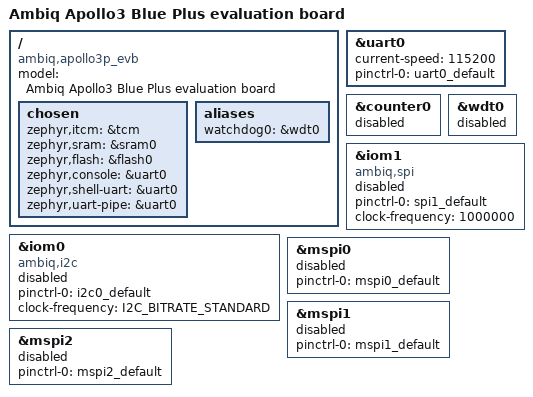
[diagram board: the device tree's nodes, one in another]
/dts-v1/;
#include <ambiq/ambiq_apollo3p_blue.dtsi>

#include "apollo3p_evb-pinctrl.dtsi"

/ {
	model = "Ambiq Apollo3 Blue Plus evaluation board";
	compatible = "ambiq,apollo3p_evb";

	chosen {
		zephyr,itcm = &tcm;
		zephyr,sram = &sram0;
		zephyr,flash = &flash0;
		zephyr,console = &uart0;
		zephyr,shell-uart = &uart0;
		zephyr,uart-pipe = &uart0;
	};

	aliases {
		watchdog0 = &wdt0;
	};
};

&uart0 {
	current-speed = <115200>;
	pinctrl-0 = <&uart0_default>;
	pinctrl-names = "default";
	status = "okay";
};

&counter0 {
	status = "disabled";
};

&wdt0 {
	status = "disabled";
};

&iom0 {
	compatible = "ambiq,i2c";
	pinctrl-0 = <&i2c0_default>;
	pinctrl-names = "default";
	clock-frequency = <I2C_BITRATE_STANDARD>;
	status = "disabled";
};

&iom1 {
	compatible = "ambiq,spi";
	pinctrl-0 = <&spi1_default>;
	pinctrl-names = "default";
	clock-frequency = <1000000>;
	status = "disabled";
};

&mspi0 {
	pinctrl-0 = <&mspi0_default>;
	pinctrl-names = "default";
	status = "disabled";
};

&mspi1 {
	pinctrl-0 = <&mspi1_default>;
	pinctrl-names = "default";
	status = "disabled";
};

&mspi2 {
	pinctrl-0 = <&mspi2_default>;
	pinctrl-names = "default";
	status = "disabled";
};
